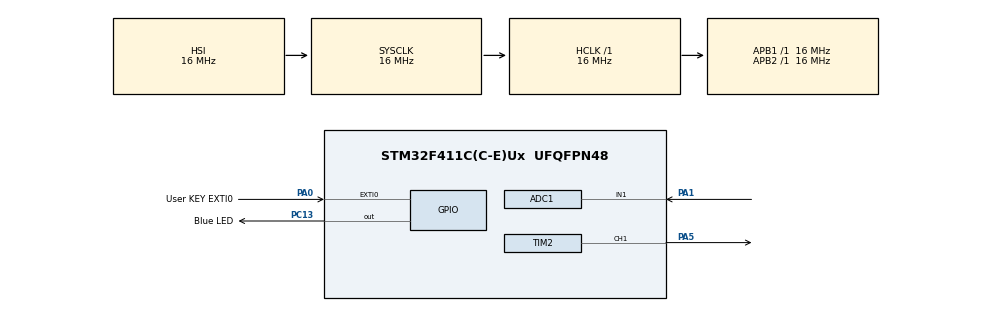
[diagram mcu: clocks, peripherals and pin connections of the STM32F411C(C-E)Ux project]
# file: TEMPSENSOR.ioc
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ADC1.Channel-0\#ChannelRegularConversion=ADC_CHANNEL_1
ADC1.Channel-1\#ChannelRegularConversion=ADC_CHANNEL_TEMPSENSOR
ADC1.Channel-2\#ChannelRegularConversion=ADC_CHANNEL_VREFINT
ADC1.ContinuousConvMode=DISABLE
ADC1.DMAContinuousRequests=ENABLE
ADC1.NbrOfConversion=3
ADC1.NbrOfConversionFlag=1
ADC1.Rank-0\#ChannelRegularConversion=1
ADC1.Rank-1\#ChannelRegularConversion=2
ADC1.Rank-2\#ChannelRegularConversion=3
ADC1.SamplingTime-0\#ChannelRegularConversion=ADC_SAMPLETIME_3CYCLES
ADC1.SamplingTime-1\#ChannelRegularConversion=ADC_SAMPLETIME_84CYCLES
ADC1.SamplingTime-2\#ChannelRegularConversion=ADC_SAMPLETIME_84CYCLES
ADC1.master=1
Dma.ADC1.0.Direction=DMA_PERIPH_TO_MEMORY
Dma.ADC1.0.FIFOMode=DMA_FIFOMODE_DISABLE
Dma.ADC1.0.Instance=DMA2_Stream0
Dma.ADC1.0.MemDataAlignment=DMA_MDATAALIGN_WORD
Dma.ADC1.0.MemInc=DMA_MINC_ENABLE
Dma.ADC1.0.Mode=DMA_CIRCULAR
Dma.ADC1.0.PeriphDataAlignment=DMA_PDATAALIGN_WORD
Dma.ADC1.0.PeriphInc=DMA_PINC_DISABLE
Dma.ADC1.0.Priority=DMA_PRIORITY_LOW
Dma.Request0=ADC1
Mcu.Family=STM32F4
Mcu.Name=STM32F411C(C-E)Ux
Mcu.Package=UFQFPN48
NVIC.ADC_IRQn=true\:1\:0\:true\:false\:true\:true\:true\:true
NVIC.DMA2_Stream0_IRQn=true\:0\:0\:true\:false\:true\:true\:true\:true
NVIC.EXTI0_IRQn=true\:0\:0\:true\:false\:true\:true\:true\:true
NVIC.PriorityGroup=NVIC_PRIORITYGROUP_4
NVIC.TIM2_IRQn=true\:0\:0\:true\:false\:true\:true\:true\:true
PA0-WKUP.GPIO_Label=User KEY EXTI0
PA0-WKUP.GPIO_PuPd=GPIO_PULLUP
PA0-WKUP.Signal=GPXTI0
PA1.Signal=ADCx_IN1
PA13.Mode=Serial_Wire
PA13.Signal=SYS_JTMS-SWDIO
PA14.Mode=Serial_Wire
PA14.Signal=SYS_JTCK-SWCLK
PA5.Signal=S_TIM2_CH1_ETR
PC13-ANTI_TAMP.GPIO_Label=Blue LED
PC13-ANTI_TAMP.GPIO_ModeDefaultOutputPP=GPIO_MODE_OUTPUT_OD
PC13-ANTI_TAMP.GPIO_PuPd=GPIO_NOPULL
PC13-ANTI_TAMP.PinState=GPIO_PIN_SET
PC13-ANTI_TAMP.Signal=GPIO_Output
PC14-OSC32_IN.Mode=LSE-External-Oscillator
PC14-OSC32_IN.Signal=RCC_OSC32_IN
PC15-OSC32_OUT.Mode=LSE-External-Oscillator
PC15-OSC32_OUT.Signal=RCC_OSC32_OUT
PH0\ -\ OSC_IN.Mode=HSE-External-Oscillator
PH0\ -\ OSC_IN.Signal=RCC_OSC_IN
PH1\ -\ OSC_OUT.Mode=HSE-External-Oscillator
PH1\ -\ OSC_OUT.Signal=RCC_OSC_OUT
ProjectManager.HeapSize=0x200
ProjectManager.StackSize=0x400
ProjectManager.TargetToolchain=CMake
RCC.AHBFreq_Value=16000000
RCC.APB1Freq_Value=16000000
RCC.APB2Freq_Value=16000000
RCC.CortexFreq_Value=16000000
RCC.HSE_VALUE=25000000
RCC.HSI_VALUE=16000000
RCC.SYSCLKFreq_VALUE=16000000
RCC.VCOOutputFreq_Value=192000000
SH.ADCx_IN1.0=ADC1_IN1,IN1
SH.S_TIM2_CH1_ETR.0=TIM2_CH1,PWM Generation1 CH1
TIM2.AutoReloadPreload=TIM_AUTORELOAD_PRELOAD_ENABLE
TIM2.Channel-PWM\ Generation1\ CH1=TIM_CHANNEL_1
TIM2.Period=4095
TIM2.Prescaler=3
VP_ADC1_TempSens_Input.Mode=IN-TempSens
VP_ADC1_Vref_Input.Mode=IN-Vrefint
VP_TIM2_VS_ClockSourceINT.Mode=Internal
board=custom

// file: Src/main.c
/* USER CODE BEGIN Header */
/**
  ******************************************************************************
  * @file           : main.c
  * @brief          : Main program body
  ******************************************************************************
  * @attention
  *
  * Copyright (c) 2026 STMicroelectronics.
  * All rights reserved.
  *
  * This software is licensed under terms that can be found in the LICENSE file
  * in the root directory of this software component.
  * If no LICENSE file comes with this software, it is provided AS-IS.
  *
  ******************************************************************************
  */
/* USER CODE END Header */
#include "main.h"

/* USER CODE BEGIN Includes */
#include <stdbool.h>
/* USER CODE END Includes */

/* USER CODE BEGIN PD */
#define AVG_SLOPE   2.5f     // mV/°C
#define V_AT_25C    0.76f    // Volts
#define V_REF_INT   1.21f    // Internal reference voltage
/* USER CODE END PD */

ADC_HandleTypeDef hadc1;
DMA_HandleTypeDef hdma_adc1;

TIM_HandleTypeDef htim2;

/* USER CODE BEGIN PV */
bool BLUELED = 0;
uint32_t AD_RES_BUFFER[3];
uint16_t ADC1IN1,TEMPSENSOR,VREFINT;
float voltage1,v_ref,v_sense,temp;
/* USER CODE END PV */

void SystemClock_Config(void);
static void MX_GPIO_Init(void);
static void MX_DMA_Init(void);
static void MX_ADC1_Init(void);
static void MX_TIM2_Init(void);

int main(void)
{

  /* MCU Configuration--------------------------------------------------------*/

  /* Reset of all peripherals, Initializes the Flash interface and the Systick. */
  HAL_Init();

  /* Configure the system clock */
  SystemClock_Config();

  /* Initialize all configured peripherals */
  MX_GPIO_Init();
  MX_DMA_Init();
  MX_ADC1_Init();
  MX_TIM2_Init();
  /* USER CODE BEGIN 2 */
HAL_TIM_PWM_Start_IT(&htim2,TIM_CHANNEL_1);
  /* USER CODE END 2 */

  /* Infinite loop */
  /* USER CODE BEGIN WHILE */
  while (1)
  {
       if (BLUELED)
      HAL_GPIO_WritePin(GPIOC, GPIO_PIN_13, GPIO_PIN_RESET); // LED ON
    else
      HAL_GPIO_WritePin(GPIOC, GPIO_PIN_13, GPIO_PIN_SET); // LED OFF
    /* USER CODE END WHILE */

  }
}

void SystemClock_Config(void)
{
  RCC_OscInitTypeDef RCC_OscInitStruct = {0};
  RCC_ClkInitTypeDef RCC_ClkInitStruct = {0};

  /** Configure the main internal regulator output voltage
  */
  __HAL_RCC_PWR_CLK_ENABLE();
  __HAL_PWR_VOLTAGESCALING_CONFIG(PWR_REGULATOR_VOLTAGE_SCALE1);

  /** Initializes the RCC Oscillators according to the specified parameters
  * in the RCC_OscInitTypeDef structure.
  */
  RCC_OscInitStruct.OscillatorType = RCC_OSCILLATORTYPE_HSI;
  RCC_OscInitStruct.HSIState = RCC_HSI_ON;
  RCC_OscInitStruct.HSICalibrationValue = RCC_HSICALIBRATION_DEFAULT;
  RCC_OscInitStruct.PLL.PLLState = RCC_PLL_NONE;
  if (HAL_RCC_OscConfig(&RCC_OscInitStruct) != HAL_OK)
  {
    Error_Handler();
  }

  /** Initializes the CPU, AHB and APB buses clocks
  */
  RCC_ClkInitStruct.ClockType = RCC_CLOCKTYPE_HCLK|RCC_CLOCKTYPE_SYSCLK
                              |RCC_CLOCKTYPE_PCLK1|RCC_CLOCKTYPE_PCLK2;
  RCC_ClkInitStruct.SYSCLKSource = RCC_SYSCLKSOURCE_HSI;
  RCC_ClkInitStruct.AHBCLKDivider = RCC_SYSCLK_DIV1;
  RCC_ClkInitStruct.APB1CLKDivider = RCC_HCLK_DIV1;
  RCC_ClkInitStruct.APB2CLKDivider = RCC_HCLK_DIV1;

  if (HAL_RCC_ClockConfig(&RCC_ClkInitStruct, FLASH_LATENCY_0) != HAL_OK)
  {
    Error_Handler();
  }
}

static void MX_ADC1_Init(void)
{

  ADC_ChannelConfTypeDef sConfig = {0};

  /** Configure the global features of the ADC (Clock, Resolution, Data Alignment and number of conversion)
  */
  hadc1.Instance = ADC1;
  hadc1.Init.ClockPrescaler = ADC_CLOCK_SYNC_PCLK_DIV2;
  hadc1.Init.Resolution = ADC_RESOLUTION_12B;
  hadc1.Init.ScanConvMode = ENABLE;
  hadc1.Init.ContinuousConvMode = DISABLE;
  hadc1.Init.DiscontinuousConvMode = DISABLE;
  hadc1.Init.ExternalTrigConvEdge = ADC_EXTERNALTRIGCONVEDGE_NONE;
  hadc1.Init.ExternalTrigConv = ADC_SOFTWARE_START;
  hadc1.Init.DataAlign = ADC_DATAALIGN_RIGHT;
  hadc1.Init.NbrOfConversion = 3;
  hadc1.Init.DMAContinuousRequests = ENABLE;
  hadc1.Init.EOCSelection = ADC_EOC_SINGLE_CONV;
  if (HAL_ADC_Init(&hadc1) != HAL_OK)
  {
    Error_Handler();
  }

  /** Configure for the selected ADC regular channel its corresponding rank in the sequencer and its sample time.
  */
  sConfig.Channel = ADC_CHANNEL_1;
  sConfig.Rank = 1;
  sConfig.SamplingTime = ADC_SAMPLETIME_3CYCLES;
  if (HAL_ADC_ConfigChannel(&hadc1, &sConfig) != HAL_OK)
  {
    Error_Handler();
  }

  /** Configure for the selected ADC regular channel its corresponding rank in the sequencer and its sample time.
  */
  sConfig.Channel = ADC_CHANNEL_TEMPSENSOR;
  sConfig.Rank = 2;
  sConfig.SamplingTime = ADC_SAMPLETIME_84CYCLES;
  if (HAL_ADC_ConfigChannel(&hadc1, &sConfig) != HAL_OK)
  {
    Error_Handler();
  }

  /** Configure for the selected ADC regular channel its corresponding rank in the sequencer and its sample time.
  */
  sConfig.Channel = ADC_CHANNEL_VREFINT;
  sConfig.Rank = 3;
  if (HAL_ADC_ConfigChannel(&hadc1, &sConfig) != HAL_OK)
  {
    Error_Handler();
  }

}

static void MX_TIM2_Init(void)
{

  TIM_ClockConfigTypeDef sClockSourceConfig = {0};
  TIM_MasterConfigTypeDef sMasterConfig = {0};
  TIM_OC_InitTypeDef sConfigOC = {0};

  htim2.Instance = TIM2;
  htim2.Init.Prescaler = 3;
  htim2.Init.CounterMode = TIM_COUNTERMODE_UP;
  htim2.Init.Period = 4095;
  htim2.Init.ClockDivision = TIM_CLOCKDIVISION_DIV1;
  htim2.Init.AutoReloadPreload = TIM_AUTORELOAD_PRELOAD_ENABLE;
  if (HAL_TIM_Base_Init(&htim2) != HAL_OK)
  {
    Error_Handler();
  }
  sClockSourceConfig.ClockSource = TIM_CLOCKSOURCE_INTERNAL;
  if (HAL_TIM_ConfigClockSource(&htim2, &sClockSourceConfig) != HAL_OK)
  {
    Error_Handler();
  }
  if (HAL_TIM_PWM_Init(&htim2) != HAL_OK)
  {
    Error_Handler();
  }
  sMasterConfig.MasterOutputTrigger = TIM_TRGO_RESET;
  sMasterConfig.MasterSlaveMode = TIM_MASTERSLAVEMODE_DISABLE;
  if (HAL_TIMEx_MasterConfigSynchronization(&htim2, &sMasterConfig) != HAL_OK)
  {
    Error_Handler();
  }
  sConfigOC.OCMode = TIM_OCMODE_PWM1;
  sConfigOC.Pulse = 0;
  sConfigOC.OCPolarity = TIM_OCPOLARITY_HIGH;
  sConfigOC.OCFastMode = TIM_OCFAST_DISABLE;
  if (HAL_TIM_PWM_ConfigChannel(&htim2, &sConfigOC, TIM_CHANNEL_1) != HAL_OK)
  {
    Error_Handler();
  }
  HAL_TIM_MspPostInit(&htim2);

}

static void MX_DMA_Init(void)
{

  /* DMA controller clock enable */
  __HAL_RCC_DMA2_CLK_ENABLE();

  /* DMA interrupt init */
  /* DMA2_Stream0_IRQn interrupt configuration */
  HAL_NVIC_SetPriority(DMA2_Stream0_IRQn, 0, 0);
  HAL_NVIC_EnableIRQ(DMA2_Stream0_IRQn);

}

static void MX_GPIO_Init(void)
{
  GPIO_InitTypeDef GPIO_InitStruct = {0};

  /* GPIO Ports Clock Enable */
  __HAL_RCC_GPIOC_CLK_ENABLE();
  __HAL_RCC_GPIOH_CLK_ENABLE();
  __HAL_RCC_GPIOA_CLK_ENABLE();

  /*Configure GPIO pin Output Level */
  HAL_GPIO_WritePin(Blue_LED_GPIO_Port, Blue_LED_Pin, GPIO_PIN_SET);

  /*Configure GPIO pin : Blue_LED_Pin */
  GPIO_InitStruct.Pin = Blue_LED_Pin;
  GPIO_InitStruct.Mode = GPIO_MODE_OUTPUT_OD;
  GPIO_InitStruct.Pull = GPIO_NOPULL;
  GPIO_InitStruct.Speed = GPIO_SPEED_FREQ_LOW;
  HAL_GPIO_Init(Blue_LED_GPIO_Port, &GPIO_InitStruct);

  /*Configure GPIO pin : User_KEY_EXTI0_Pin */
  GPIO_InitStruct.Pin = User_KEY_EXTI0_Pin;
  GPIO_InitStruct.Mode = GPIO_MODE_IT_RISING;
  GPIO_InitStruct.Pull = GPIO_PULLUP;
  HAL_GPIO_Init(User_KEY_EXTI0_GPIO_Port, &GPIO_InitStruct);

  /* EXTI interrupt init*/
  HAL_NVIC_SetPriority(EXTI0_IRQn, 0, 0);
  HAL_NVIC_EnableIRQ(EXTI0_IRQn);

}

void Error_Handler(void)
{
  __disable_irq();
  while (1)
  {
  }
}
